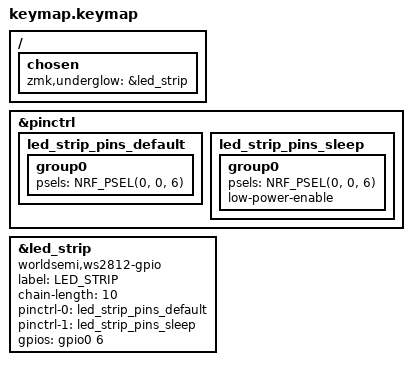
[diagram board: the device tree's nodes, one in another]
&pinctrl {
    led_strip_pins_default: led_strip_pins_default {
        group0 {
            psels = <NRF_PSEL(0, 0, 6)>; // Change to your LED strip data pin
        };
    };
    led_strip_pins_sleep: led_strip_pins_sleep {
        group0 {
            psels = <NRF_PSEL(0, 0, 6)>; // Change to your LED strip data pin
            low-power-enable;
        };
    };
};

&led_strip {
    compatible = "worldsemi,ws2812-gpio";
    status = "okay";
    label = "LED_STRIP";
    chain-length = <10>;  // Set to your number of LEDs

    pinctrl-0 = <&led_strip_pins_default>;
    pinctrl-1 = <&led_strip_pins_sleep>;
    pinctrl-names = "default", "sleep";
    gpios = <&gpio0 6 0>;
};

/ {
    chosen {
        zmk,underglow = &led_strip;
    };
};
